# LPC55S16 register map
Vendor: nxp.com; File version: 1.0
CPU: CM33 r2p0, little endian, MPU, FPU, VTOR, 3 interrupt priority bits
Registers are 32-bit, read-write, reset 0x0 unless marked. A register's access mark holds for its fields unless they carry their own. Offsets are from the block's base; [hi:lo] are bit positions; lines under a group give offsets from that group; {n}, {i} and the like mark numbered series.

## PUF_SRAM_CTRL — PUF SRAM Control
Base 0x4003B000; alternate view of PUF
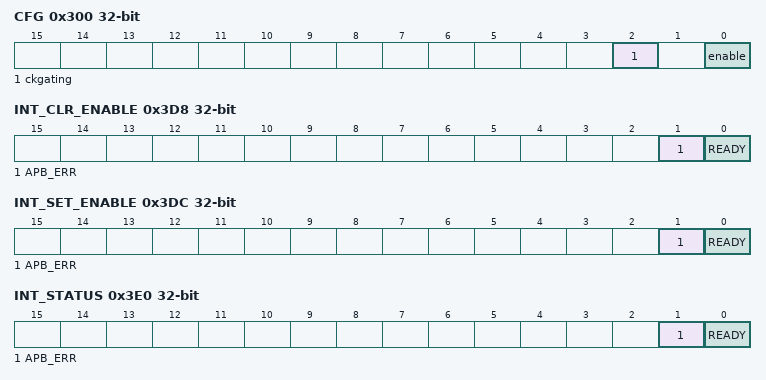
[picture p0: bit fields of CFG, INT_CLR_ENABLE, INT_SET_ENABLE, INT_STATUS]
0x300 CFG — Configuration Register
  [2] ckgating — PUF SRAM Clock Gating control
  [0] enable — PUF SRAM Controller activation
0x304 STATUS
  [0] READY ro — PUF SRAM Controller State
0x3D8 INT_CLR_ENABLE wo — Interrupt Enable Clear Register
  [1] APB_ERR — APB_ERR Interrupt Enable clear
  [0] READY — READY Interrupt Enable clear
0x3DC INT_SET_ENABLE wo — Interrupt Enable Set Register
  [1] APB_ERR — APB_ERR Interrupt Enable set
  [0] READY — READY Interrupt Enable set
0x3E0 INT_STATUS — Interrupt Status Register
  [1] APB_ERR ro — APB_ERR Interrupt Status
  [0] READY ro — READY Interrupt Status
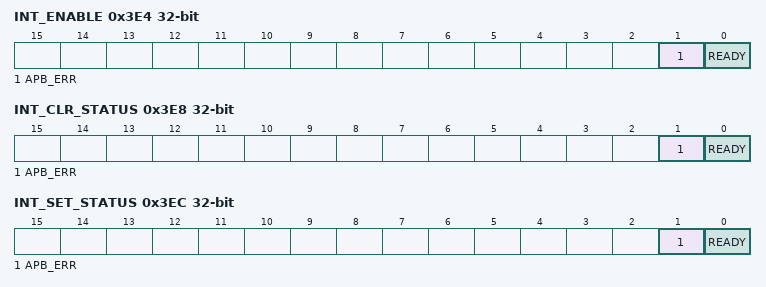
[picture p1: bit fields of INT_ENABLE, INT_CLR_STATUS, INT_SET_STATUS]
0x3E4 INT_ENABLE — Interrupt Enable Register
  [1] APB_ERR ro — APB_ERR Interrupt Enable
  [0] READY ro — READY Interrupt Enable
0x3E8 INT_CLR_STATUS wo — Interrupt Status Clear Register
  [1] APB_ERR — APB_ERR Interrupt Status Clear
  [0] READY — READY Interrupt Status clear
0x3EC INT_SET_STATUS wo — Interrupt Status set
  [1] APB_ERR — APB_ERR Interrupt Status Set
  [0] READY — READY Interrupt Status set

## PLU — LPC80X Programmable Logic Unit (PLU)
Base 0x4003D000
{0x0+0x20*i} LUT[{i}] (i=0..25) group
  {0x0+4j} LUT_INP_MUX{j} (j=0..4) — LUTn input x MUX
    [5:0] LUTn_INPx — Selects the input source to be connected to LUT0 input0. For each LUT, the slot associated with the output from LUTn itself is tied low.
      {v}=plu_inputs{v} (The PLU primary inputs {v}.) (v=0..5); {v}=lut_outputs{v-6} (The output of LUT{v-6}.) (v=6..31); {v}=state{v-32} (v=32..35)
{0x800+4i} LUT_TRUTH[{i}] (i=0..25) — Specifies the Truth Table contents for LUTLUTn
  [31:0] LUTn_TRUTH — Specifies the Truth Table contents for LUT0..
0x900 OUTPUTS — Provides the current state of the 8 designated PLU Outputs.
  [7:0] OUTPUT_STATE ro — Provides the current state of the 8 designated PLU Outputs..
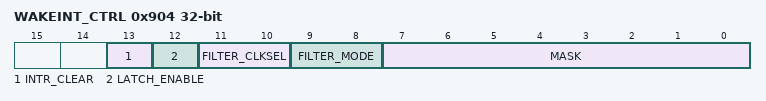
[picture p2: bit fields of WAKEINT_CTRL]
0x904 WAKEINT_CTRL — Wakeup interrupt control for PLU
  [13] INTR_CLEAR write-1-clears — Write to clear wakeint_latched
  [12] LATCH_ENABLE — latch the interrupt , then can be cleared with next bit INTR_CLEAR
  [11:10] FILTER_CLKSEL — hclk is divided by 2**filter_clksel.
    0=FRO1MHZ (Selects the 1 MHz low-power oscillator as the filter clock.); 1=FRO12MHZ (Selects the 12 Mhz FRO as the filter clock.); 2=OTHER_CLOCK (Selects a third filter clock source, if provided.)
  [9:8] FILTER_MODE — control input of the PLU, add filtering for glitch.
    0=BYPASS (Bypass mode.); 1=FILTER1CLK (Filter 1 clock period.); 2=FILTER2CLK (Filter 2 clock period.); 3=FILTER3CLK (Filter 3 clock period.)
  [7:0] MASK — Interrupt mask (which of the 8 PLU Outputs contribute to interrupt)
{0xC00+4i} OUTPUT_MUX[{i}] (i=0..7) — Selects the source to be connected to PLU Output OUTPUT_n
  [4:0] OUTPUTn — Selects the source to be connected to PLU Output 0.
    {v}=plu_output{v} (The PLU output {v}.) (v=0..25); {v}=state{v-26} (v=26..29)

## FLEXCOMM0 — Flexcomm serial communication
Base 0x40086000
Same registers: FLEXCOMM1 0x40087000, FLEXCOMM2 0x40088000, FLEXCOMM3 0x40089000, FLEXCOMM4 0x4008A000, FLEXCOMM5 0x40096000, FLEXCOMM6 0x40097000, FLEXCOMM7 0x40098000, FLEXCOMM8 0x4009F000
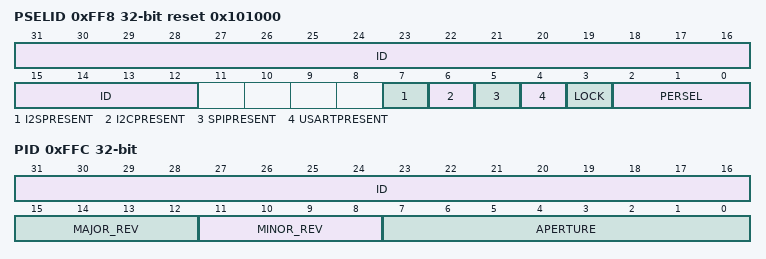
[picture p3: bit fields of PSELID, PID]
0xFF8 PSELID reset 0x101000 — Peripheral Select and Flexcomm ID register.
  [31:12] ID ro — Flexcomm ID.
  [7] I2SPRESENT ro — I 2S present indicator. This field is Read-only.
    0=NOT_PRESENT (This Flexcomm does not include the I2S function.); 1=PRESENT (This Flexcomm includes the I2S function.)
  [6] I2CPRESENT ro — I2C present indicator. This field is Read-only.
    0=NOT_PRESENT (This Flexcomm does not include the I2C function.); 1=PRESENT (This Flexcomm includes the I2C function.)
  [5] SPIPRESENT ro — SPI present indicator. This field is Read-only.
    0=NOT_PRESENT (This Flexcomm does not include the SPI function.); 1=PRESENT (This Flexcomm includes the SPI function.)
  [4] USARTPRESENT ro — USART present indicator. This field is Read-only.
    0=NOT_PRESENT (This Flexcomm does not include the USART function.); 1=PRESENT (This Flexcomm includes the USART function.)
  [3] LOCK — Lock the peripheral select. This field is writable by software.
    0=UNLOCKED (Peripheral select can be changed by software.); 1=LOCKED (Peripheral select is locked and cannot be changed until this Flexcomm or the entire device is reset.)
  [2:0] PERSEL — Peripheral Select. This field is writable by software.
    0=NO_PERIPH_SELECTED (No peripheral selected.); 1=USART (USART function selected.); 2=SPI (SPI function selected.); 3=I2C (I2C function selected.); 4=I2S_TRANSMIT (I2S transmit function selected.); 5=I2S_RECEIVE (I2S receive function selected.)
0xFFC PID ro — Peripheral identification register.
  [31:16] ID — Module identifier for the selected function.
  [15:12] MAJOR_REV — Major revision of module implementation.
  [11:8] MINOR_REV — Minor revision of module implementation.
  [7:0] APERTURE — size aperture for the register port on the bus (APB or AHB).
